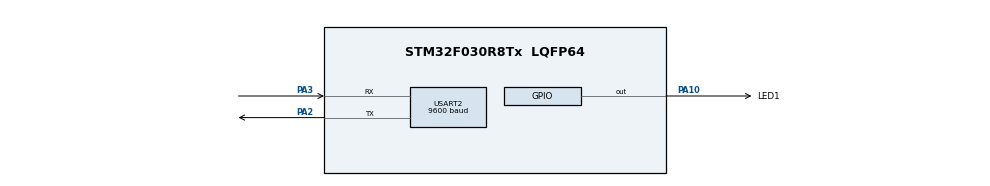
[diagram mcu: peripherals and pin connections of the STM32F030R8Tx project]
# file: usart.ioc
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Mcu.Family=STM32F0
Mcu.Name=STM32F030R8Tx
Mcu.Package=LQFP64
NVIC.USART2_IRQn=true\:0\:0\:false\:false\:true\:true\:true\:true
PA10.GPIO_Label=LED1
PA10.Signal=GPIO_Output
PA13.Mode=Serial_Wire
PA13.Signal=SYS_SWDIO
PA14.Mode=Serial_Wire
PA14.Signal=SYS_SWCLK
PA2.Mode=Asynchronous
PA2.Signal=USART2_TX
PA3.Mode=Asynchronous
PA3.Signal=USART2_RX
PC14-OSC32_IN.Mode=LSE-External-Oscillator
PC14-OSC32_IN.Signal=RCC_OSC32_IN
PC15-OSC32_OUT.Mode=LSE-External-Oscillator
PC15-OSC32_OUT.Signal=RCC_OSC32_OUT
PF0-OSC_IN.Mode=HSE-External-Oscillator
PF0-OSC_IN.Signal=RCC_OSC_IN
PF1-OSC_OUT.Mode=HSE-External-Oscillator
PF1-OSC_OUT.Signal=RCC_OSC_OUT
ProjectManager.HeapSize=0x200
ProjectManager.StackSize=0x400
ProjectManager.TargetToolchain=STM32CubeIDE
RCC.AHBFreq_Value=8000000
RCC.APB1Freq_Value=8000000
RCC.APB1TimFreq_Value=8000000
RCC.HCLKFreq_Value=8000000
USART2.BaudRate=9600
USART2.VirtualMode-Asynchronous=VM_ASYNC
board=custom

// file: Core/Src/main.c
/* USER CODE BEGIN Header */
/**
  ******************************************************************************
  * @file           : main.c
  * @brief          : Main program body
  ******************************************************************************
  * @attention
  *
  * Copyright (c) 2024 STMicroelectronics.
  * All rights reserved.
  *
  * This software is licensed under terms that can be found in the LICENSE file
  * in the root directory of this software component.
  * If no LICENSE file comes with this software, it is provided AS-IS.
  *
  ******************************************************************************
  */
/* USER CODE END Header */
#include "main.h"

/* USER CODE BEGIN PD */
#define BUFFER_SIZE
/* USER CODE END PD */

UART_HandleTypeDef huart2;

void SystemClock_Config(void);
static void MX_GPIO_Init(void);
static void MX_USART2_UART_Init(void);

int main(void)
{

  /* MCU Configuration--------------------------------------------------------*/

  /* Reset of all peripherals, Initializes the Flash interface and the Systick. */
  HAL_Init();

  /* Configure the system clock */
  SystemClock_Config();

  /* Initialize all configured peripherals */
  MX_GPIO_Init();
  MX_USART2_UART_Init();
  /* USER CODE BEGIN 2 */
uint8_t transmitBuffer[] = "Hello world!\n\r"; // Объявляем массив с переменной ввиде отправляемой строки
uint8_t buffer[]= ""; // Служебный массив, для хранения переменной

HAL_UART_Transmit_IT(&huart2,transmitBuffer,14); // Отправка массива (какой usart, какой буффер, сколько бит отправлять)

  /* USER CODE END 2 */

  /* Infinite loop */

  /* USER CODE BEGIN WHILE */
  while (1)
  {
	  HAL_UART_Receive(&huart2,(uint8_t*)buffer, 1,100 ); // Получение данных (какой usart,какой буффер, сколько бит получать, окно получения данных)
	  if (buffer[0] == '1'){ // ВАЖНО кавычки (" ") считаются как отдельная строка, а апострофы (' ') как отдельная переменная
		  HAL_GPIO_WritePin(LED1_GPIO_Port, LED1_Pin,GPIO_PIN_SET);
	  }
	  if (buffer[0] == '0'){
		  HAL_GPIO_WritePin(LED1_GPIO_Port, LED1_Pin,GPIO_PIN_RESET);
	  }

    /* USER CODE END WHILE */

  }
}

void SystemClock_Config(void)
{
  RCC_OscInitTypeDef RCC_OscInitStruct = {0};
  RCC_ClkInitTypeDef RCC_ClkInitStruct = {0};

  /** Initializes the RCC Oscillators according to the specified parameters
  * in the RCC_OscInitTypeDef structure.
  */
  RCC_OscInitStruct.OscillatorType = RCC_OSCILLATORTYPE_HSI;
  RCC_OscInitStruct.HSIState = RCC_HSI_ON;
  RCC_OscInitStruct.HSICalibrationValue = RCC_HSICALIBRATION_DEFAULT;
  RCC_OscInitStruct.PLL.PLLState = RCC_PLL_NONE;
  if (HAL_RCC_OscConfig(&RCC_OscInitStruct) != HAL_OK)
  {
    Error_Handler();
  }

  /** Initializes the CPU, AHB and APB buses clocks
  */
  RCC_ClkInitStruct.ClockType = RCC_CLOCKTYPE_HCLK|RCC_CLOCKTYPE_SYSCLK
                              |RCC_CLOCKTYPE_PCLK1;
  RCC_ClkInitStruct.SYSCLKSource = RCC_SYSCLKSOURCE_HSI;
  RCC_ClkInitStruct.AHBCLKDivider = RCC_SYSCLK_DIV1;
  RCC_ClkInitStruct.APB1CLKDivider = RCC_HCLK_DIV1;

  if (HAL_RCC_ClockConfig(&RCC_ClkInitStruct, FLASH_LATENCY_0) != HAL_OK)
  {
    Error_Handler();
  }
}

static void MX_USART2_UART_Init(void)
{

  huart2.Instance = USART2;
  huart2.Init.BaudRate = 9600;
  huart2.Init.WordLength = UART_WORDLENGTH_8B;
  huart2.Init.StopBits = UART_STOPBITS_1;
  huart2.Init.Parity = UART_PARITY_NONE;
  huart2.Init.Mode = UART_MODE_TX_RX;
  huart2.Init.HwFlowCtl = UART_HWCONTROL_NONE;
  huart2.Init.OverSampling = UART_OVERSAMPLING_16;
  huart2.Init.OneBitSampling = UART_ONE_BIT_SAMPLE_DISABLE;
  huart2.AdvancedInit.AdvFeatureInit = UART_ADVFEATURE_NO_INIT;
  if (HAL_UART_Init(&huart2) != HAL_OK)
  {
    Error_Handler();
  }

}

static void MX_GPIO_Init(void)
{
  GPIO_InitTypeDef GPIO_InitStruct = {0};

  /* GPIO Ports Clock Enable */
  __HAL_RCC_GPIOC_CLK_ENABLE();
  __HAL_RCC_GPIOF_CLK_ENABLE();
  __HAL_RCC_GPIOA_CLK_ENABLE();

  /*Configure GPIO pin Output Level */
  HAL_GPIO_WritePin(LED1_GPIO_Port, LED1_Pin, GPIO_PIN_RESET);

  /*Configure GPIO pin : LED1_Pin */
  GPIO_InitStruct.Pin = LED1_Pin;
  GPIO_InitStruct.Mode = GPIO_MODE_OUTPUT_PP;
  GPIO_InitStruct.Pull = GPIO_NOPULL;
  GPIO_InitStruct.Speed = GPIO_SPEED_FREQ_LOW;
  HAL_GPIO_Init(LED1_GPIO_Port, &GPIO_InitStruct);

}

void Error_Handler(void)
{
  __disable_irq();
  while (1)
  {
  }
}
